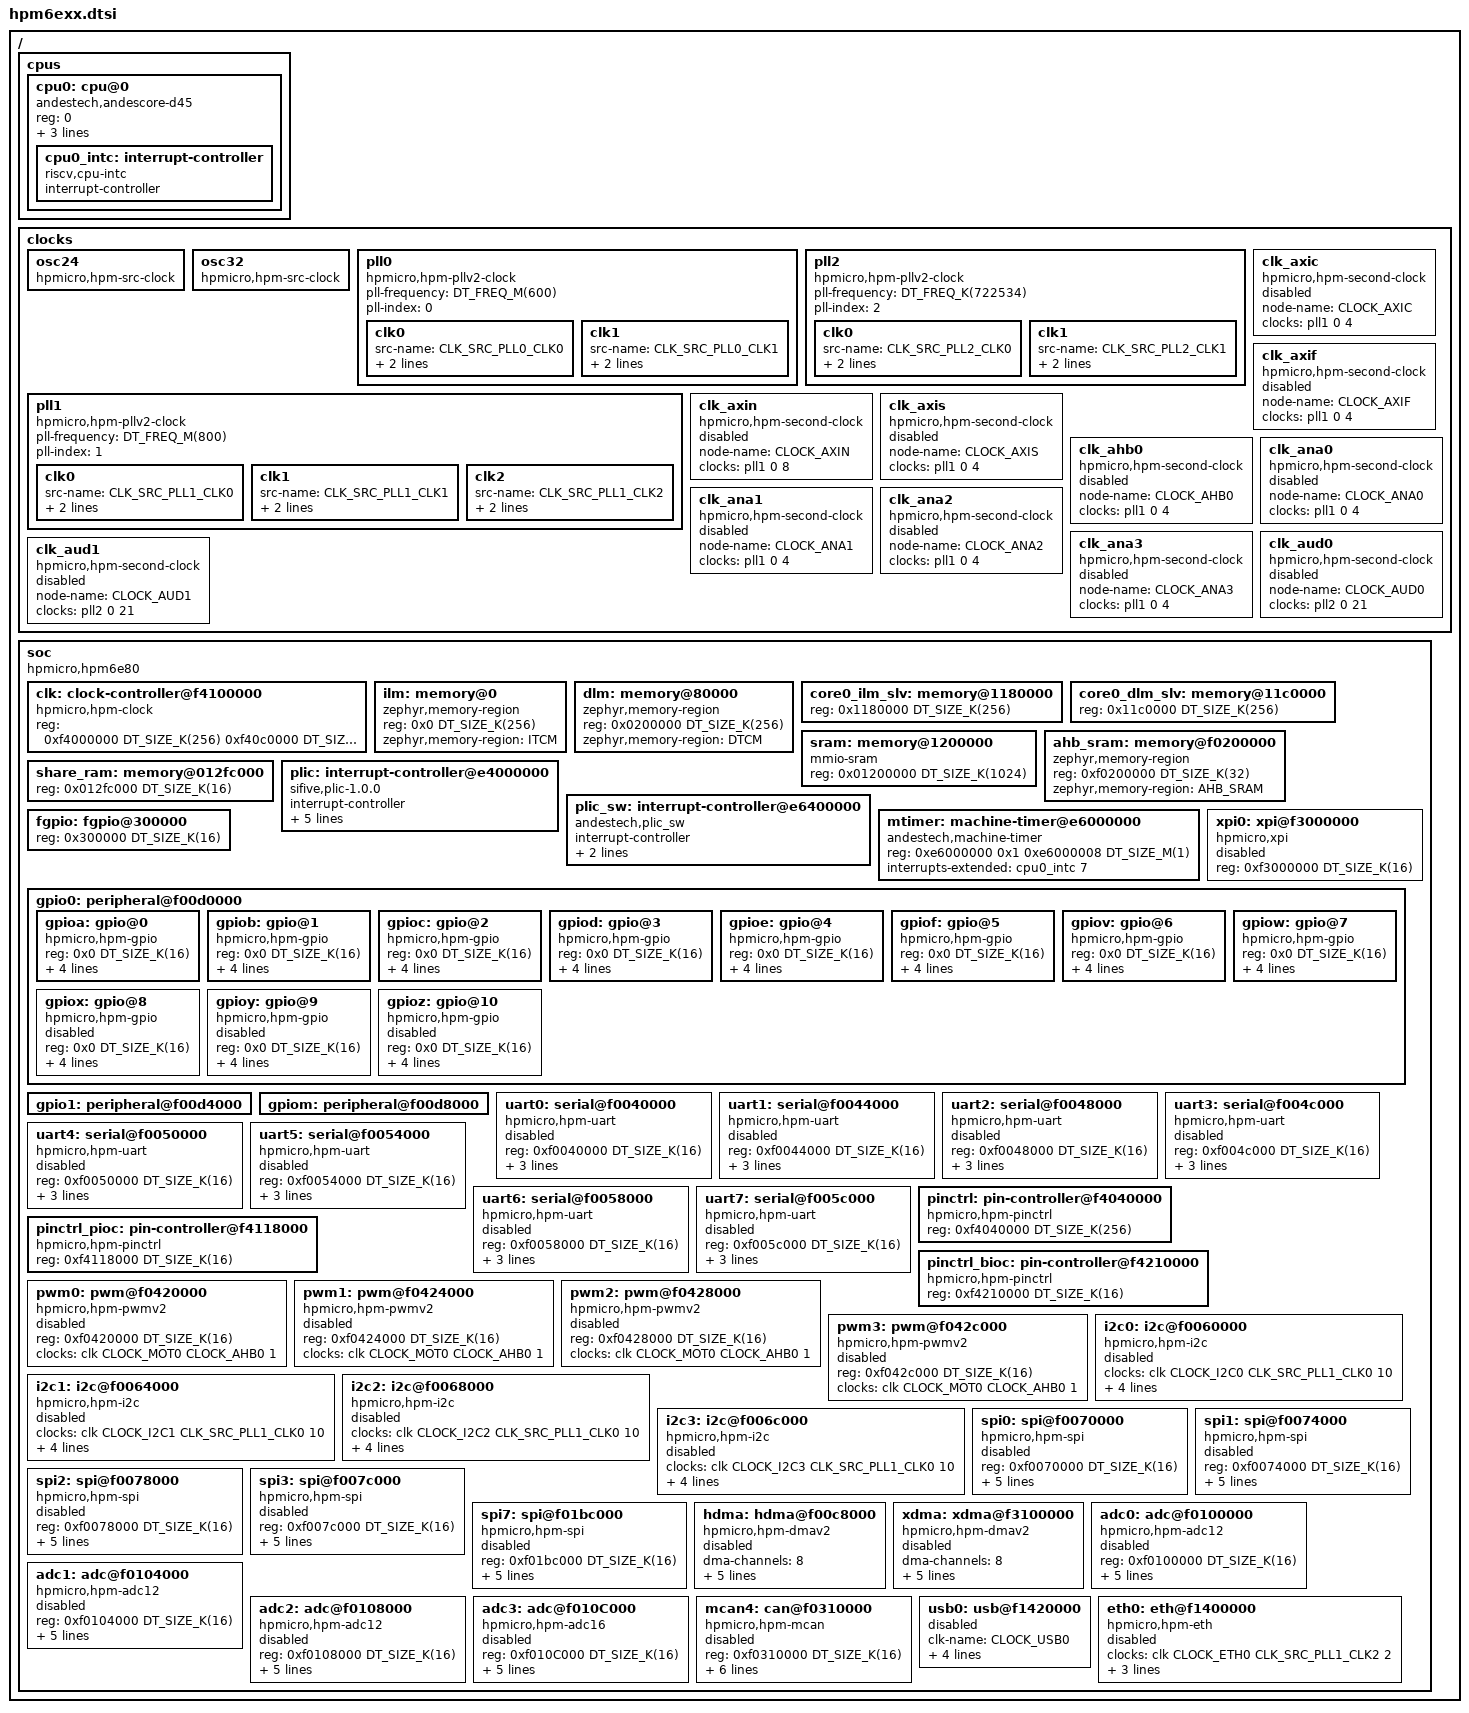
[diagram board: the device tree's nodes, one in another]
/*
 * Copyright 2025 HPMicro
 * SPDX-License-Identifier: Apache-2.0
 */

/dts-v1/;
#include <zephyr/dt-bindings/gpio/gpio.h>
#include <zephyr/dt-bindings/i2c/i2c.h>
#include <dt-bindings/clock/hpm6e80-clocks.h>
#include <mem.h>
#include <freq.h>

/ {
    #address-cells = <1>;
    #size-cells = <1>;

    cpus {
        #address-cells = <1>;
        #size-cells = <0>;
        cpu0: cpu@0 {
            compatible = "andestech,andescore-d45", "riscv";
            reg = <0>;
            status = "okay";
            riscv,isa = "rv32gc_xandes";
            i-cache-line-size = <64>;
            d-cache-line-size = <64>;

            cpu0_intc: interrupt-controller {
                compatible = "riscv,cpu-intc";
                #address-cells = <0>;
                #interrupt-cells = <1>;
                interrupt-controller;
            };
        };
    };

    clocks {
        osc24: osc24 {
            #clock-cells = <2>;
            compatible = "hpmicro,hpm-src-clock";
        };

        osc32: osc32 {
            #clock-cells = <2>;
            compatible = "hpmicro,hpm-src-clock";
        };

        pll0: pll0 {
            #clock-cells = <2>;
            compatible = "hpmicro,hpm-pllv2-clock";
            pll-frequency = <DT_FREQ_M(600)>;
            pll-index = <0>;

            clk0 {
                src-name = <CLK_SRC_PLL0_CLK0>;
                div-i = <0>;
                div-p = <0>;
            };

            clk1 {
                src-name = <CLK_SRC_PLL0_CLK1>;
                div-i = <1>;
                div-p = <1>;
            };
        };

        pll1: pll1 {
            #clock-cells = <2>;
            compatible = "hpmicro,hpm-pllv2-clock";
            pll-frequency = <DT_FREQ_M(800)>;
            pll-index = <1>;

            clk0 {
                src-name = <CLK_SRC_PLL1_CLK0>;
                div-i = <0>;
                div-p = <0>;
            };

            clk1 {
                src-name = <CLK_SRC_PLL1_CLK1>;
                div-i = <1>;
                div-p = <7>;
            };

            clk2 {
                src-name = <CLK_SRC_PLL1_CLK2>;
                div-i = <2>;
                div-p = <11>;
            };
        };

        pll2: pll2 {
            #clock-cells = <2>;
            compatible = "hpmicro,hpm-pllv2-clock";
            pll-frequency = <DT_FREQ_K(722534)>;
            pll-index = <2>;

            clk0 {
                src-name = <CLK_SRC_PLL2_CLK0>;
                div-i = <0>;
                div-p = <2>;
            };

            clk1 {
                src-name = <CLK_SRC_PLL2_CLK1>;
                div-i = <1>;
                div-p = <3>;
            };
        };

        clk_axic: clk_axic {
            #clock-cells = <2>;
            compatible = "hpmicro,hpm-second-clock";
            node-name = <CLOCK_AXIC>;
            clocks = <&pll1 0 4>;
            status = "disabled";
        };

        clk_axif: clk_axif {
            #clock-cells = <2>;
            compatible = "hpmicro,hpm-second-clock";
            node-name = <CLOCK_AXIF>;
            clocks = <&pll1 0 4>;
            status = "disabled";
        };

        clk_axin: clk_axin {
            #clock-cells = <2>;
            compatible = "hpmicro,hpm-second-clock";
            node-name = <CLOCK_AXIN>;
            clocks = <&pll1 0 8>;
            status = "disabled";
        };

        clk_axis: clk_axis {
            #clock-cells = <2>;
            compatible = "hpmicro,hpm-second-clock";
            node-name = <CLOCK_AXIS>;
            clocks = <&pll1 0 4>;
            status = "disabled";
        };

        clk_ahb0: clk_ahb0 {
            #clock-cells = <2>;
            compatible = "hpmicro,hpm-second-clock";
            node-name = <CLOCK_AHB0>;
            clocks = <&pll1 0 4>;
            status = "disabled";
        };

        clk_ana0: clk_ana0 {
            #clock-cells = <2>;
            compatible = "hpmicro,hpm-second-clock";
            node-name = <CLOCK_ANA0>;
            clocks = <&pll1 0 4>;
            status = "disabled";
        };

        clk_ana1: clk_ana1 {
            #clock-cells = <2>;
            compatible = "hpmicro,hpm-second-clock";
            node-name = <CLOCK_ANA1>;
            clocks = <&pll1 0 4>;
            status = "disabled";
        };

        clk_ana2: clk_ana2 {
            #clock-cells = <2>;
            compatible = "hpmicro,hpm-second-clock";
            node-name = <CLOCK_ANA2>;
            clocks = <&pll1 0 4>;
            status = "disabled";
        };

        clk_ana3: clk_ana3 {
            #clock-cells = <2>;
            compatible = "hpmicro,hpm-second-clock";
            node-name = <CLOCK_ANA3>;
            clocks = <&pll1 0 4>;
            status = "disabled";
        };

        clk_aud0: clk_aud0 {
            #clock-cells = <2>;
            compatible = "hpmicro,hpm-second-clock";
            node-name = <CLOCK_AUD0>;
            clocks = <&pll2 0 21>;
            status = "disabled";
        };

        clk_aud1: clk_aud1 {
            #clock-cells = <2>;
            compatible = "hpmicro,hpm-second-clock";
            node-name = <CLOCK_AUD1>;
            clocks = <&pll2 0 21>;
            status = "disabled";
        };
    };

    soc {
        #address-cells = <1>;
        #size-cells = <1>;
        compatible = "hpmicro,hpm6e80";
        ranges;

        clk: clock-controller@f4100000 {
            compatible = "hpmicro,hpm-clock";
            reg = <0xf4000000 DT_SIZE_K(256)
                0xf40c0000 DT_SIZE_K(256)>;
            reg-names = "sysctl", "pllv2";
            status = "okay";
            #clock-cells = <3>;
        };

        ilm: memory@0 {
            compatible = "zephyr,memory-region";
            reg = <0x0 DT_SIZE_K(256)>;
            zephyr,memory-region = "ITCM";
        };

        dlm: memory@80000 {
            compatible = "zephyr,memory-region";
            reg = <0x0200000 DT_SIZE_K(256)>;
            zephyr,memory-region = "DTCM";
        };

        core0_ilm_slv: memory@1180000 {
            reg = <0x1180000 DT_SIZE_K(256)>;
        };

        core0_dlm_slv: memory@11c0000 {
            reg = <0x11c0000 DT_SIZE_K(256)>;
        };

        sram: memory@1200000 {
            compatible = "mmio-sram";
            reg = <0x01200000 DT_SIZE_K(1024)>;
        };

        ahb_sram: memory@f0200000 {
            compatible = "zephyr,memory-region";
            reg = <0xf0200000 DT_SIZE_K(32)>;
            zephyr,memory-region = "AHB_SRAM";
        };

        share_ram: memory@012fc000 {
            reg = <0x012fc000 DT_SIZE_K(16)>;
        };

        plic: interrupt-controller@e4000000 {
            compatible = "sifive,plic-1.0.0";
            #address-cells = <1>;
            #interrupt-cells = <2>;
            interrupt-controller;
            reg = <    0xe4000000 0x00001000
                0xe4002000 0x00000800
                0xe4200000 0x00010000 >;
            reg-names = "prio", "irq_en", "reg";
            riscv,max-priority = <255>;
            riscv,ndev = <1023>;
            interrupts-extended = <&cpu0_intc 11>;
        };

        plic_sw: interrupt-controller@e6400000 {
            compatible = "andestech,plic_sw";
            #address-cells = <1>;
            #interrupt-cells = <2>;
            interrupt-controller;
            reg = <0xe6400000 DT_SIZE_M(4)>;
            interrupts-extended = <&cpu0_intc 3>;
        };

        mtimer: machine-timer@e6000000 {
            compatible = "andestech,machine-timer";
            reg = <0xe6000000 0x1
            0xe6000008 DT_SIZE_M(1)>;
            interrupts-extended = <&cpu0_intc 7>;
        };

        fgpio: fgpio@300000 {
            reg = <0x300000 DT_SIZE_K(16)>;
        };

        xpi0: xpi@f3000000 {
            compatible = "hpmicro,xpi";
            reg = <0xf3000000 DT_SIZE_K(16)>;
            #address-cells = <1>;
            #size-cells = <1>;
            status = "disabled";
        };

        gpio0: peripheral@f00d0000 {
            #address-cells = <1>;
            #size-cells = <1>;
            ranges = <0x0 0xf00d0000 DT_SIZE_K(16)>;
        };

        gpio1: peripheral@f00d4000 {
            #address-cells = <1>;
            #size-cells = <1>;
            ranges = <0x0 0xf00d4000 DT_SIZE_K(16)>;
        };

        gpiom: peripheral@f00d8000 { 
            #address-cells = <1>;
            #size-cells = <1>;
            ranges = <0x0 0xf00d8000 DT_SIZE_K(16)>;
        };

        uart0: serial@f0040000 {
            compatible = "hpmicro,hpm-uart";
            reg = <0xf0040000 DT_SIZE_K(16)>;
            interrupts = <31 1>, <27 1>;
            interrupt-names = "uart", "idletimer";
            clocks = <&clk CLOCK_UART0 CLK_SRC_PLL1_CLK0 10>;
            interrupt-parent = <&plic>;
            status = "disabled";
        };

        uart1: serial@f0044000 {
            compatible = "hpmicro,hpm-uart";
            reg = <0xf0044000 DT_SIZE_K(16)>;
            interrupts = <32 1>, <27 1>;
            interrupt-names = "uart", "idletimer";
            clocks = <&clk CLOCK_UART1 CLK_SRC_PLL1_CLK0 10>;
            interrupt-parent = <&plic>;
            status = "disabled";
        };

        uart2: serial@f0048000 {
            compatible = "hpmicro,hpm-uart";
            reg = <0xf0048000 DT_SIZE_K(16)>;
            interrupts = <33 1>, <27 1>;
            interrupt-names = "uart", "idletimer";
            clocks = <&clk CLOCK_UART2 CLK_SRC_PLL1_CLK0 10>;
            interrupt-parent = <&plic>;
            status = "disabled";
        };

        uart3: serial@f004c000 {
            compatible = "hpmicro,hpm-uart";
            reg = <0xf004c000 DT_SIZE_K(16)>;
            interrupts = <34 1>, <27 1>;
            interrupt-names = "uart", "idletimer";
            clocks = <&clk CLOCK_UART3 CLK_SRC_PLL1_CLK0 10>;
            interrupt-parent = <&plic>;
            status = "disabled";
        };

        uart4: serial@f0050000 {
            compatible = "hpmicro,hpm-uart";
            reg = <0xf0050000 DT_SIZE_K(16)>;
            interrupts = <35 1>, <27 1>;
            interrupt-names = "uart", "idletimer";
            clocks = <&clk CLOCK_UART4 CLK_SRC_PLL1_CLK0 10>;
            interrupt-parent = <&plic>;
            status = "disabled";
        };

        uart5: serial@f0054000 {
            compatible = "hpmicro,hpm-uart";
            reg = <0xf0054000 DT_SIZE_K(16)>;
            interrupts = <36 1>, <27 1>;
            interrupt-names = "uart", "idletimer";
            clocks = <&clk CLOCK_UART5 CLK_SRC_PLL1_CLK0 10>;
            interrupt-parent = <&plic>;
            status = "disabled";
        };

        uart6: serial@f0058000 {
            compatible = "hpmicro,hpm-uart";
            reg = <0xf0058000 DT_SIZE_K(16)>;
            interrupts = <37 1>, <27 1>;
            interrupt-names = "uart", "idletimer";
            clocks = <&clk CLOCK_UART6 CLK_SRC_PLL1_CLK0 10>;
            interrupt-parent = <&plic>;
            status = "disabled";
        };

        uart7: serial@f005c000 {
            compatible = "hpmicro,hpm-uart";
            reg = <0xf005c000 DT_SIZE_K(16)>;
            interrupts = <38 1>, <27 1>;
            interrupt-names = "uart", "idletimer";
            clocks = <&clk CLOCK_UART7 CLK_SRC_PLL1_CLK0 10>;
            interrupt-parent = <&plic>;
            status = "disabled";
        };

        pinctrl: pin-controller@f4040000 {
            compatible = "hpmicro,hpm-pinctrl";
            reg = <0xf4040000 DT_SIZE_K(256)>;
            status = "okay";
        };

        pinctrl_pioc: pin-controller@f4118000 {
            compatible = "hpmicro,hpm-pinctrl";
            reg = <0xf4118000 DT_SIZE_K(16)>;
            status = "okay";
        };

        pinctrl_bioc: pin-controller@f4210000 {
            compatible = "hpmicro,hpm-pinctrl";
            reg = <0xf4210000 DT_SIZE_K(16)>;
            status = "okay";
        };

        pwm0: pwm@f0420000 {
            compatible = "hpmicro,hpm-pwmv2";
            reg = <0xf0420000 DT_SIZE_K(16)>;
            clocks = <&clk CLOCK_MOT0 CLOCK_AHB0 1>;
            status = "disabled";
            #pwm-cells = <3>;
        };

        pwm1: pwm@f0424000 {
            compatible = "hpmicro,hpm-pwmv2";
            reg = <0xf0424000 DT_SIZE_K(16)>;
            clocks = <&clk CLOCK_MOT0 CLOCK_AHB0 1>;
            status = "disabled";
            #pwm-cells = <3>;
        };

        pwm2: pwm@f0428000 {
            compatible = "hpmicro,hpm-pwmv2";
            reg = <0xf0428000 DT_SIZE_K(16)>;
            clocks = <&clk CLOCK_MOT0 CLOCK_AHB0 1>;
            status = "disabled";
            #pwm-cells = <3>;
        };

        pwm3: pwm@f042c000 {
            compatible = "hpmicro,hpm-pwmv2";
            reg = <0xf042c000 DT_SIZE_K(16)>;
            clocks = <&clk CLOCK_MOT0 CLOCK_AHB0 1>;
            status = "disabled";
            #pwm-cells = <3>;
        };

        i2c0: i2c@f0060000 {
            compatible = "hpmicro,hpm-i2c";
            #address-cells = <1>;
            #size-cells = <0>;
            clocks = <&clk CLOCK_I2C0 CLK_SRC_PLL1_CLK0 10>;
            clock-frequency = <I2C_BITRATE_STANDARD>;
            reg = <0xf0060000 DT_SIZE_K(16)>;
            interrupts = <39 1>;
            interrupt-parent = <&plic>;
            status = "disabled";
        };

        i2c1: i2c@f0064000 {
            compatible = "hpmicro,hpm-i2c";
            #address-cells = <1>;
            #size-cells = <0>;
            clocks = <&clk CLOCK_I2C1 CLK_SRC_PLL1_CLK0 10>;
            clock-frequency = <I2C_BITRATE_STANDARD>;
            reg = <0xf0064000 DT_SIZE_K(16)>;
            interrupts = <40 1>;
            interrupt-parent = <&plic>;
            status = "disabled";
        };

        i2c2: i2c@f0068000 {
            compatible = "hpmicro,hpm-i2c";
            #address-cells = <1>;
            #size-cells = <0>;
            clocks = <&clk CLOCK_I2C2 CLK_SRC_PLL1_CLK0 10>;
            clock-frequency = <I2C_BITRATE_STANDARD>;
            reg = <0xf0068000 DT_SIZE_K(16)>;
            interrupts = <41 1>;
            interrupt-parent = <&plic>;
            status = "disabled";
        };

        i2c3: i2c@f006c000 {
            compatible = "hpmicro,hpm-i2c";
            #address-cells = <1>;
            #size-cells = <0>;
            clocks = <&clk CLOCK_I2C3 CLK_SRC_PLL1_CLK0 10>;
            clock-frequency = <I2C_BITRATE_STANDARD>;
            reg = <0xf006c000 DT_SIZE_K(16)>;
            interrupts = <42 1>;
            interrupt-parent = <&plic>;
            status = "disabled";
        };

        spi0: spi@f0070000 {
            compatible = "hpmicro,hpm-spi";
            reg = <0xf0070000 DT_SIZE_K(16)>;
            clocks = <&clk CLOCK_SPI0 CLK_SRC_PLL1_CLK0 10>;
            interrupts = <43 1>;
            interrupt-parent = <&plic>;
            status = "disabled";
            #address-cells = <1>;
            #size-cells = <0>;
            cs-sck-delay = <3>;
            cs-minimum-high-time = <11>;
        };

        spi1: spi@f0074000 {
            compatible = "hpmicro,hpm-spi";
            reg = <0xf0074000 DT_SIZE_K(16)>;
            clocks = <&clk CLOCK_SPI1 CLK_SRC_PLL1_CLK0 10>;
            interrupts = <44 1>;
            interrupt-parent = <&plic>;
            status = "disabled";
            #address-cells = <1>;
            #size-cells = <0>;
            cs-sck-delay = <3>;
            cs-minimum-high-time = <11>;
        };

        spi2: spi@f0078000 {
            compatible = "hpmicro,hpm-spi";
            reg = <0xf0078000 DT_SIZE_K(16)>;
            clocks = <&clk CLOCK_SPI2 CLK_SRC_PLL1_CLK0 10>;
            interrupts = <45 1>;
            interrupt-parent = <&plic>;
            status = "disabled";
            #address-cells = <1>;
            #size-cells = <0>;
            cs-sck-delay = <3>;
            cs-minimum-high-time = <11>;
        };


        spi3: spi@f007c000 {
            compatible = "hpmicro,hpm-spi";
            reg = <0xf007c000 DT_SIZE_K(16)>;
            clocks = <&clk CLOCK_SPI3 CLK_SRC_PLL1_CLK0 10>;
            interrupts = <46 1>;
            interrupt-parent = <&plic>;
            status = "disabled";
            #address-cells = <1>;
            #size-cells = <0>;
            cs-sck-delay = <3>;
            cs-minimum-high-time = <11>;
        };

        spi7: spi@f01bc000 {
            compatible = "hpmicro,hpm-spi";
            reg = <0xf01bc000 DT_SIZE_K(16)>;
            clocks = <&clk CLOCK_SPI7 CLK_SRC_PLL1_CLK0 10>;
            interrupts = <89 1>;
            interrupt-parent = <&plic>;
            status = "disabled";
            #address-cells = <1>;
            #size-cells = <0>;
            cs-sck-delay = <3>;
            cs-minimum-high-time = <11>;
        };

        hdma: hdma@f00c8000 {
            #dma-cells = <2>;
            compatible = "hpmicro,hpm-dmav2";
            dma-channels = <8>;
            dma-requests = <116>;
            reg = <0xf00c8000 DT_SIZE_K(16)>,
                <0xf00c4000 DT_SIZE_K(16)>; /* DMAMUX base */
            interrupts = <56 1>;
            interrupt-parent = <&plic>;
            status = "disabled";
        };

        xdma: xdma@f3100000 {
            #dma-cells = <2>;
            compatible = "hpmicro,hpm-dmav2";
            dma-channels = <8>;
            dma-requests = <116>;
            reg = <0xf3100000 DT_SIZE_K(16)>,
                <0xf00c4000 DT_SIZE_K(16)>; /* DMAMUX base */
            interrupts = <140 1>;
            interrupt-parent = <&plic>;
            status = "disabled";
        };

        adc0: adc@f0100000 {
            compatible = "hpmicro,hpm-adc12";
            reg = <0xf0100000 DT_SIZE_K(16)>;
            interrupts = <58 1>;
            interrupt-parent = <&plic>;
            clocks = <&clk CLOCK_ADC0 CLK_ADC_SRC_ANA0 1>, <&clk CLOCK_ANA0 CLK_SRC_PLL1_CLK0 4>;
            sample-time = <20>;
            status = "disabled";
            #io-channel-cells = <1>;
        };

        adc1: adc@f0104000 {
            compatible = "hpmicro,hpm-adc12";
            reg = <0xf0104000 DT_SIZE_K(16)>;
            interrupts = <59 1>;
            interrupt-parent = <&plic>;
            clocks = <&clk CLOCK_ADC1 CLK_ADC_SRC_ANA1 1>, <&clk CLOCK_ANA1 CLK_SRC_PLL1_CLK0 4>;
            sample-time = <20>;
            status = "disabled";
            #io-channel-cells = <1>;
        };

        adc2: adc@f0108000 {
            compatible = "hpmicro,hpm-adc12";
            reg = <0xf0108000 DT_SIZE_K(16)>;
            interrupts = <60 1>;
            interrupt-parent = <&plic>;
            clocks = <&clk CLOCK_ADC2 CLK_ADC_SRC_ANA2 1>, <&clk CLOCK_ANA2 CLK_SRC_PLL1_CLK0 4>;
            sample-time = <20>;
            status = "disabled";
            #io-channel-cells = <1>;
        };

        adc3: adc@f010C000 {
            compatible = "hpmicro,hpm-adc16";
            reg = <0xf010C000 DT_SIZE_K(16)>;
            interrupts = <61 1>;
            interrupt-parent = <&plic>;
            clocks = <&clk CLOCK_ADC3 CLK_ADC_SRC_ANA3 1>, <&clk CLOCK_ANA3 CLK_SRC_PLL1_CLK0 4>;
            sample-time = <20>;
            status = "disabled";
            #io-channel-cells = <1>;
        };

        mcan4: can@f0310000 {
                compatible = "hpmicro,hpm-mcan";
                reg = <0xf0310000 DT_SIZE_K(16)>;
                interrupts = <94 1>;
                interrupt-parent = <&plic>;
                clk-name = <CLOCK_CAN4>;
                clk-source = <CLK_SRC_PLL1_CLK0>;
                clk-divider = <10>;
                bus-speed = <500000>;
                status = "disabled";
        };

        usb0: usb@f1420000 {
                clk-name = <CLOCK_USB0>;
                reg = <0xf1420000 DT_SIZE_K(16)>;
                interrupts = <127 1>;
                interrupt-parent = <&plic>;
                num-bidir-endpoints = <8>;
                status = "disabled";
        };

	eth0: eth@f1400000 {
            compatible = "hpmicro,hpm-eth";
            clocks = <&clk CLOCK_ETH0 CLK_SRC_PLL1_CLK2 2>;
            reg = <0xf1400000 DT_SIZE_K(16)>;
            interrupts = <125 1>;
            interrupt-parent = <&plic>;
            status = "disabled";
        };
    };
};

&gpio0 {
    gpioa: gpio@0 {
        compatible = "hpmicro,hpm-gpio";
        reg = <0x0 DT_SIZE_K(16)>;
        gpio-controller;
        #gpio-cells = <2>;
        hpmicro-gpio-port = <0>;
        interrupts = <1 1>;
        interrupt-parent = <&plic>;
    };

    gpiob: gpio@1 {
        compatible = "hpmicro,hpm-gpio";
        reg = <0x0 DT_SIZE_K(16)>;
        gpio-controller;
        #gpio-cells = <2>;
        hpmicro-gpio-port = <1>;
        interrupts = <2 1>;
        interrupt-parent = <&plic>;
    };

    gpioc: gpio@2 {
        compatible = "hpmicro,hpm-gpio";
        reg = <0x0 DT_SIZE_K(16)>;
        gpio-controller;
        #gpio-cells = <2>;
        hpmicro-gpio-port = <2>;
        interrupts = <3 1>;
        interrupt-parent = <&plic>;
    };

    gpiod: gpio@3 {
        compatible = "hpmicro,hpm-gpio";
        reg = <0x0 DT_SIZE_K(16)>;
        gpio-controller;
        #gpio-cells = <2>;
        hpmicro-gpio-port = <3>;
        interrupts = <4 1>;
        interrupt-parent = <&plic>;
    };

    gpioe: gpio@4 {
        compatible = "hpmicro,hpm-gpio";
        reg = <0x0 DT_SIZE_K(16)>;
        gpio-controller;
        #gpio-cells = <2>;
        hpmicro-gpio-port = <4>;
        interrupts = <5 1>;
        interrupt-parent = <&plic>;
    };

    gpiof: gpio@5 {
        compatible = "hpmicro,hpm-gpio";
        reg = <0x0 DT_SIZE_K(16)>;
        gpio-controller;
        #gpio-cells = <2>;
        hpmicro-gpio-port = <5>;
        interrupts = <6 1>;
        interrupt-parent = <&plic>;
    };

    gpiov: gpio@6 {
        compatible = "hpmicro,hpm-gpio";
        reg = <0x0 DT_SIZE_K(16)>;
        gpio-controller;
        #gpio-cells = <2>;
        hpmicro-gpio-port = <6>;
        interrupts = <7 1>;
        interrupt-parent = <&plic>;
    };

    gpiow: gpio@7 {
        compatible = "hpmicro,hpm-gpio";
        reg = <0x0 DT_SIZE_K(16)>;
        gpio-controller;
        #gpio-cells = <2>;
        hpmicro-gpio-port = <7>;
        interrupts = <8 1>;
        interrupt-parent = <&plic>;
    };

    gpiox: gpio@8 {
        compatible = "hpmicro,hpm-gpio";
        reg = <0x0 DT_SIZE_K(16)>;
        gpio-controller;
        #gpio-cells = <2>;
        hpmicro-gpio-port = <8>;
        interrupt-parent = <&plic>;
        interrupts = <9 1>;
        status = "disabled";
    };

    gpioy: gpio@9 {
        compatible = "hpmicro,hpm-gpio";
        reg = <0x0 DT_SIZE_K(16)>;
        gpio-controller;
        #gpio-cells = <2>;
        hpmicro-gpio-port = <9>;
        interrupts = <10 1>;
        interrupt-parent = <&plic>;
        status = "disabled";
    };

    gpioz: gpio@10 {
        compatible = "hpmicro,hpm-gpio";
        reg = <0x0 DT_SIZE_K(16)>;
        gpio-controller;
        #gpio-cells = <2>;
        hpmicro-gpio-port = <10>;
        interrupts = <11 1>;
        interrupt-parent = <&plic>;
        status = "disabled";
    };
};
